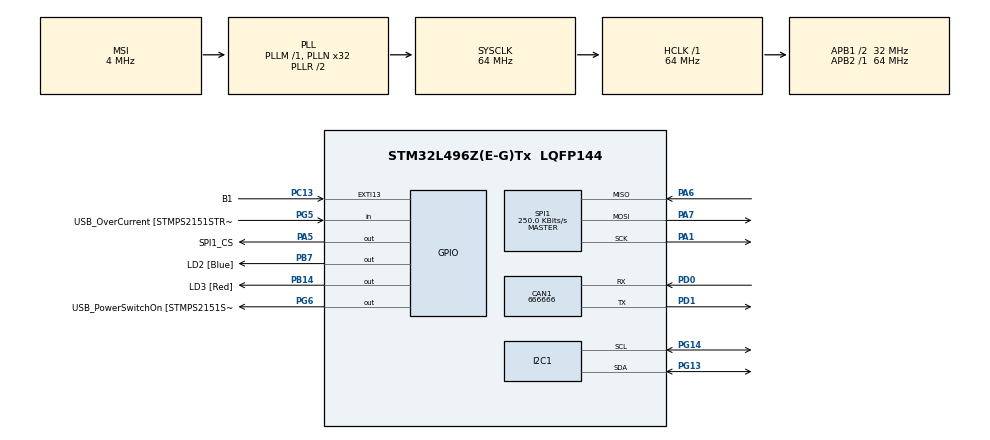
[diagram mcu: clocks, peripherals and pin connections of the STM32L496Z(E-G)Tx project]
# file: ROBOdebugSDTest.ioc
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CAN1.CalculateBaudRate=666666
CAN1.CalculateTimeBit=1500
CAN1.CalculateTimeQuantum=500.0
I2C1.Timing=0x00B07CB4
Mcu.Family=STM32L4
Mcu.Name=STM32L496Z(E-G)Tx
Mcu.Package=LQFP144
NVIC.PriorityGroup=NVIC_PRIORITYGROUP_4
PA1.GPIO_PuPd=GPIO_PULLUP
PA1.Mode=Full_Duplex_Master
PA1.Signal=SPI1_SCK
PA10.GPIO_Label=USB_ID
PA10.Signal=USB_OTG_FS_ID
PA11.GPIO_Label=USB_DM
PA11.Signal=USB_OTG_FS_DM
PA12.GPIO_Label=USB_DP
PA12.Signal=USB_OTG_FS_DP
PA13\ (JTMS/SWDIO).GPIO_Label=TMS
PA13\ (JTMS/SWDIO).Mode=Trace_Asynchronous_SW
PA13\ (JTMS/SWDIO).Signal=SYS_JTMS-SWDIO
PA14\ (JTCK/SWCLK).GPIO_Label=TCK
PA14\ (JTCK/SWCLK).Mode=Trace_Asynchronous_SW
PA14\ (JTCK/SWCLK).Signal=SYS_JTCK-SWCLK
PA5.GPIO_Label=SPI1_CS
PA5.GPIO_PuPd=GPIO_PULLUP
PA5.PinState=GPIO_PIN_SET
PA5.Signal=GPIO_Output
PA6.GPIO_PuPd=GPIO_PULLUP
PA6.Mode=Full_Duplex_Master
PA6.Signal=SPI1_MISO
PA7.GPIO_PuPd=GPIO_PULLUP
PA7.Mode=Full_Duplex_Master
PA7.Signal=SPI1_MOSI
PA8.GPIO_Label=USB_SOF [TP1]
PA8.Signal=USB_OTG_FS_SOF
PA9.GPIO_Label=USB_VBUS
PA9.Signal=USB_OTG_FS_VBUS
PB14.GPIO_Label=LD3 [Red]
PB14.Signal=GPIO_Output
PB3\ (JTDO/TRACESWO).GPIO_Label=SWO
PB3\ (JTDO/TRACESWO).Mode=Trace_Asynchronous_SW
PB3\ (JTDO/TRACESWO).Signal=SYS_JTDO-SWO
PB7.GPIO_Label=LD2 [Blue]
PB7.Signal=GPIO_Output
PC13.GPIO_Label=B1
PC13.Signal=GPXTI13
PC14-OSC32_IN\ (PC14).Mode=LSE-External-Oscillator
PC14-OSC32_IN\ (PC14).Signal=RCC_OSC32_IN
PC15-OSC32_OUT\ (PC15).Mode=LSE-External-Oscillator
PC15-OSC32_OUT\ (PC15).Signal=RCC_OSC32_OUT
PD0.Mode=CAN_Activate
PD0.Signal=CAN1_RX
PD1.Mode=CAN_Activate
PD1.Signal=CAN1_TX
PG13.Mode=I2C
PG13.Signal=I2C1_SDA
PG14.Mode=I2C
PG14.Signal=I2C1_SCL
PG5.GPIO_Label=USB_OverCurrent [STMPS2151STR_FAULT]
PG5.Signal=GPIO_Input
PG6.GPIO_Label=USB_PowerSwitchOn [STMPS2151STR_EN]
PG6.Signal=GPIO_Output
PG7.GPIO_Label=STLK_RX [STM32F103CBT6_PA3]
PG7.Signal=LPUART1_TX
PG8.GPIO_Label=STLK_TX [STM32F103CBT6_PA2]
PG8.Signal=LPUART1_RX
PH0-OSC_IN\ (PH0).Mode=HSE-External-Oscillator
PH0-OSC_IN\ (PH0).Signal=RCC_OSC_IN
PH1-OSC_OUT\ (PH1).Mode=HSE-External-Oscillator
PH1-OSC_OUT\ (PH1).Signal=RCC_OSC_OUT
ProjectManager.HeapSize=0x200
ProjectManager.StackSize=0x400
ProjectManager.TargetToolchain=STM32CubeIDE
RCC.48MHZClocksFreq_Value=24000000
RCC.ADCFreq_Value=48000000
RCC.AHBFreq_Value=64000000
RCC.APB1CLKDivider=RCC_HCLK_DIV2
RCC.APB1Freq_Value=32000000
RCC.APB1TimFreq_Value=64000000
RCC.APB2Freq_Value=64000000
RCC.APB2TimFreq_Value=64000000
RCC.CortexFreq_Value=64000000
RCC.HCLKFreq_Value=64000000
RCC.HSE_VALUE=8000000
RCC.HSI48_VALUE=48000000
RCC.HSI_VALUE=16000000
RCC.MSI_VALUE=4000000
RCC.PLLMUL=RCC_PLL_MUL9
RCC.PLLN=32
RCC.PLLSAI1N=24
RCC.PRESCALERUSB=RCC_USBCLKSOURCE_PLL_DIV1_5
RCC.SYSCLKFreq_VALUE=64000000
RCC.SYSCLKSource=RCC_SYSCLKSOURCE_PLLCLK
RCC.SYSCLKSourceVirtual=RCC_SYSCLKSOURCE_PLLCLK
RCC.USBFreq_Value=48000000
RCC.VCOOutputFreq_Value=128000000
SPI1.BaudRatePrescaler=SPI_BAUDRATEPRESCALER_256
SPI1.CalculateBaudRate=250.0 KBits/s
SPI1.DataSize=SPI_DATASIZE_8BIT
SPI1.Direction=SPI_DIRECTION_2LINES
SPI1.Mode=SPI_MODE_MASTER
SPI1.VirtualType=VM_MASTER
VP_FATFS_VS_Generic.Mode=User_defined
board=NUCLEO-L496ZG

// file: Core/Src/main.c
/* USER CODE BEGIN Header */
/**
  ******************************************************************************
  * @file           : main.c
  * @brief          : Main program body
  ******************************************************************************
  * @attention
  *
  * Copyright (c) 2025 STMicroelectronics.
  * All rights reserved.
  *
  * This software is licensed under terms that can be found in the LICENSE file
  * in the root directory of this software component.
  * If no LICENSE file comes with this software, it is provided AS-IS.
  *
  ******************************************************************************
  */
/* USER CODE END Header */
#include "main.h"
#include "fatfs.h"

/* USER CODE BEGIN Includes */
#include <stdlib.h>
#include <stdio.h>
#include <string.h>

/* USER CODE END Includes */

CAN_HandleTypeDef hcan1;

I2C_HandleTypeDef hi2c1;

SPI_HandleTypeDef hspi1;

void SystemClock_Config(void);
static void MX_GPIO_Init(void);
static void MX_CAN1_Init(void);
static void MX_I2C1_Init(void);
static void MX_SPI1_Init(void);

int main(void)
{

  /* MCU Configuration--------------------------------------------------------*/

  /* Reset of all peripherals, Initializes the Flash interface and the Systick. */
  HAL_Init();

  /* Configure the system clock */
  SystemClock_Config();

  /* Initialize all configured peripherals */
  MX_GPIO_Init();
  MX_CAN1_Init();
  MX_I2C1_Init();
  MX_SPI1_Init();
  MX_FATFS_Init();
//  /* USER CODE BEGIN 2 */
printf("SPI SD card test Initialing");
fflush(stdout);
HAL_Delay(1000);
FATFS FatFs;	//FatFs handle
FIL fil; 		//File handle
FRESULT fres; //Result after operations

//Open the file system
fres = f_mount(&FatFs, "", 1); //1=mount now
if (fres != FR_OK) {
	printf("f_mount error (%i)\r\n", fres);
	fflush(stdout);
	while(1);
}
DWORD free_clusters, free_sectors, total_sectors;

FATFS* getFreeFs;

fres = f_getfree("", &free_clusters, &getFreeFs);
if (fres != FR_OK) {
	printf("f_getfree error (%i)\r\n", fres);
	fflush(stdout);
	while(1);
}

//Formula comes from ChaN's documentation
total_sectors = (getFreeFs->n_fatent - 2) * getFreeFs->csize;
free_sectors = free_clusters * getFreeFs->csize;

printf("SD card stats:\r\n%10lu KiB total drive space.\r\n%10lu KiB available.\r\n", total_sectors / 2, free_sectors / 2);
fflush(stdout);
//----------------------------------------------------------------------------------
////Now let's try to open file "test.txt"
//fres = f_open(&fil, "test.txt", FA_READ);
//if (fres != FR_OK) {
//	myprintf("f_open error (%i)\r\n");
//	while(1);
//}
//myprintf("Opened 'test.txt' for reading!\r\n");
//
////Read 30 bytes from "test.txt" on the SD card
BYTE readBuf[30];
//
////We can either use f_read OR f_gets to get data out of files
////f_gets is a wrapper on f_read that does some string formatting for us
//TCHAR* rres = f_gets((TCHAR*)readBuf, 30, &fil);
//if(rres != 0) {
//	myprintf("Read string from 'test.txt' contents: %s\r\n", readBuf);
//} else {
//	myprintf("f_gets error (%i)\r\n", fres);
//}
//
//
//f_close(&fil);
//----------------------------------------------------------------------------------
//Now let's try and write a file "write.txt"
fres = f_open(&fil, "write.txt", FA_WRITE | FA_OPEN_ALWAYS | FA_CREATE_ALWAYS);
if(fres == FR_OK) {
	printf("Opened 'write.txt' for writing\r\n");
	fflush(stdout);
} else {
	printf("f_open error (%i)\r\n", fres);
	fflush(stdout);
}

//Copy in a string
strncpy((char*)readBuf, "a new file created", 19);
UINT bytesWrote;
fres = f_write(&fil, readBuf, 19, &bytesWrote);
if(fres == FR_OK) {
	printf("Wrote %i bytes to 'write.txt'!\r\n", bytesWrote);
	fflush(stdout);
} else {
	printf("f_write error (%i)\r\n");
	fflush(stdout);
}

f_close(&fil);

//We're done, so de-mount the drive
f_mount(NULL, "", 0);
  /* USER CODE END 2 */

  /* Infinite loop */
  while (1)
  {

    /* USER CODE BEGIN 3 */
	  printf("You can close the project now");
	  fflush(stdout); //flushes out everything from stdout buffer
	  HAL_Delay(5000);
  }
  // Data size - bits send per pulse
  // Pre scaler - SPI clk = sysclk/pre scaler
  /* USER CODE END 3 */
}

void SystemClock_Config(void)
{
  RCC_OscInitTypeDef RCC_OscInitStruct = {0};
  RCC_ClkInitTypeDef RCC_ClkInitStruct = {0};

  /** Configure the main internal regulator output voltage
  */
  if (HAL_PWREx_ControlVoltageScaling(PWR_REGULATOR_VOLTAGE_SCALE1) != HAL_OK)
  {
    Error_Handler();
  }

  /** Initializes the RCC Oscillators according to the specified parameters
  * in the RCC_OscInitTypeDef structure.
  */
  RCC_OscInitStruct.OscillatorType = RCC_OSCILLATORTYPE_MSI;
  RCC_OscInitStruct.MSIState = RCC_MSI_ON;
  RCC_OscInitStruct.MSICalibrationValue = 0;
  RCC_OscInitStruct.MSIClockRange = RCC_MSIRANGE_6;
  RCC_OscInitStruct.PLL.PLLState = RCC_PLL_ON;
  RCC_OscInitStruct.PLL.PLLSource = RCC_PLLSOURCE_MSI;
  RCC_OscInitStruct.PLL.PLLM = 1;
  RCC_OscInitStruct.PLL.PLLN = 32;
  RCC_OscInitStruct.PLL.PLLP = RCC_PLLP_DIV2;
  RCC_OscInitStruct.PLL.PLLQ = RCC_PLLQ_DIV2;
  RCC_OscInitStruct.PLL.PLLR = RCC_PLLR_DIV2;
  if (HAL_RCC_OscConfig(&RCC_OscInitStruct) != HAL_OK)
  {
    Error_Handler();
  }

  /** Initializes the CPU, AHB and APB buses clocks
  */
  RCC_ClkInitStruct.ClockType = RCC_CLOCKTYPE_HCLK|RCC_CLOCKTYPE_SYSCLK
                              |RCC_CLOCKTYPE_PCLK1|RCC_CLOCKTYPE_PCLK2;
  RCC_ClkInitStruct.SYSCLKSource = RCC_SYSCLKSOURCE_PLLCLK;
  RCC_ClkInitStruct.AHBCLKDivider = RCC_SYSCLK_DIV1;
  RCC_ClkInitStruct.APB1CLKDivider = RCC_HCLK_DIV2;
  RCC_ClkInitStruct.APB2CLKDivider = RCC_HCLK_DIV1;

  if (HAL_RCC_ClockConfig(&RCC_ClkInitStruct, FLASH_LATENCY_3) != HAL_OK)
  {
    Error_Handler();
  }
}

static void MX_CAN1_Init(void)
{

  hcan1.Instance = CAN1;
  hcan1.Init.Prescaler = 16;
  hcan1.Init.Mode = CAN_MODE_NORMAL;
  hcan1.Init.SyncJumpWidth = CAN_SJW_1TQ;
  hcan1.Init.TimeSeg1 = CAN_BS1_1TQ;
  hcan1.Init.TimeSeg2 = CAN_BS2_1TQ;
  hcan1.Init.TimeTriggeredMode = DISABLE;
  hcan1.Init.AutoBusOff = DISABLE;
  hcan1.Init.AutoWakeUp = DISABLE;
  hcan1.Init.AutoRetransmission = DISABLE;
  hcan1.Init.ReceiveFifoLocked = DISABLE;
  hcan1.Init.TransmitFifoPriority = DISABLE;
  if (HAL_CAN_Init(&hcan1) != HAL_OK)
  {
    Error_Handler();
  }

}

static void MX_I2C1_Init(void)
{

  hi2c1.Instance = I2C1;
  hi2c1.Init.Timing = 0x00B07CB4;
  hi2c1.Init.OwnAddress1 = 0;
  hi2c1.Init.AddressingMode = I2C_ADDRESSINGMODE_7BIT;
  hi2c1.Init.DualAddressMode = I2C_DUALADDRESS_DISABLE;
  hi2c1.Init.OwnAddress2 = 0;
  hi2c1.Init.OwnAddress2Masks = I2C_OA2_NOMASK;
  hi2c1.Init.GeneralCallMode = I2C_GENERALCALL_DISABLE;
  hi2c1.Init.NoStretchMode = I2C_NOSTRETCH_DISABLE;
  if (HAL_I2C_Init(&hi2c1) != HAL_OK)
  {
    Error_Handler();
  }

  /** Configure Analogue filter
  */
  if (HAL_I2CEx_ConfigAnalogFilter(&hi2c1, I2C_ANALOGFILTER_ENABLE) != HAL_OK)
  {
    Error_Handler();
  }

  /** Configure Digital filter
  */
  if (HAL_I2CEx_ConfigDigitalFilter(&hi2c1, 0) != HAL_OK)
  {
    Error_Handler();
  }

}

static void MX_SPI1_Init(void)
{

  /* SPI1 parameter configuration*/
  hspi1.Instance = SPI1;
  hspi1.Init.Mode = SPI_MODE_MASTER;
  hspi1.Init.Direction = SPI_DIRECTION_2LINES;
  hspi1.Init.DataSize = SPI_DATASIZE_8BIT;
  hspi1.Init.CLKPolarity = SPI_POLARITY_LOW;
  hspi1.Init.CLKPhase = SPI_PHASE_1EDGE;
  hspi1.Init.NSS = SPI_NSS_SOFT;
  hspi1.Init.BaudRatePrescaler = SPI_BAUDRATEPRESCALER_256;
  hspi1.Init.FirstBit = SPI_FIRSTBIT_MSB;
  hspi1.Init.TIMode = SPI_TIMODE_DISABLE;
  hspi1.Init.CRCCalculation = SPI_CRCCALCULATION_DISABLE;
  hspi1.Init.CRCPolynomial = 7;
  hspi1.Init.CRCLength = SPI_CRC_LENGTH_DATASIZE;
  hspi1.Init.NSSPMode = SPI_NSS_PULSE_ENABLE;
  if (HAL_SPI_Init(&hspi1) != HAL_OK)
  {
    Error_Handler();
  }

}

static void MX_GPIO_Init(void)
{
  GPIO_InitTypeDef GPIO_InitStruct = {0};

  /* GPIO Ports Clock Enable */
  __HAL_RCC_GPIOC_CLK_ENABLE();
  __HAL_RCC_GPIOH_CLK_ENABLE();
  __HAL_RCC_GPIOA_CLK_ENABLE();
  __HAL_RCC_GPIOB_CLK_ENABLE();
  __HAL_RCC_GPIOG_CLK_ENABLE();
  HAL_PWREx_EnableVddIO2();
  __HAL_RCC_GPIOD_CLK_ENABLE();

  /*Configure GPIO pin Output Level */
  HAL_GPIO_WritePin(SPI1_CS_GPIO_Port, SPI1_CS_Pin, GPIO_PIN_SET);

  /*Configure GPIO pin Output Level */
  HAL_GPIO_WritePin(GPIOB, LD3_Pin|LD2_Pin, GPIO_PIN_RESET);

  /*Configure GPIO pin Output Level */
  HAL_GPIO_WritePin(USB_PowerSwitchOn_GPIO_Port, USB_PowerSwitchOn_Pin, GPIO_PIN_RESET);

  /*Configure GPIO pin : B1_Pin */
  GPIO_InitStruct.Pin = B1_Pin;
  GPIO_InitStruct.Mode = GPIO_MODE_IT_RISING;
  GPIO_InitStruct.Pull = GPIO_NOPULL;
  HAL_GPIO_Init(B1_GPIO_Port, &GPIO_InitStruct);

  /*Configure GPIO pin : SPI1_CS_Pin */
  GPIO_InitStruct.Pin = SPI1_CS_Pin;
  GPIO_InitStruct.Mode = GPIO_MODE_OUTPUT_PP;
  GPIO_InitStruct.Pull = GPIO_PULLUP;
  GPIO_InitStruct.Speed = GPIO_SPEED_FREQ_LOW;
  HAL_GPIO_Init(SPI1_CS_GPIO_Port, &GPIO_InitStruct);

  /*Configure GPIO pins : LD3_Pin LD2_Pin */
  GPIO_InitStruct.Pin = LD3_Pin|LD2_Pin;
  GPIO_InitStruct.Mode = GPIO_MODE_OUTPUT_PP;
  GPIO_InitStruct.Pull = GPIO_NOPULL;
  GPIO_InitStruct.Speed = GPIO_SPEED_FREQ_LOW;
  HAL_GPIO_Init(GPIOB, &GPIO_InitStruct);

  /*Configure GPIO pin : USB_OverCurrent_Pin */
  GPIO_InitStruct.Pin = USB_OverCurrent_Pin;
  GPIO_InitStruct.Mode = GPIO_MODE_INPUT;
  GPIO_InitStruct.Pull = GPIO_NOPULL;
  HAL_GPIO_Init(USB_OverCurrent_GPIO_Port, &GPIO_InitStruct);

  /*Configure GPIO pin : USB_PowerSwitchOn_Pin */
  GPIO_InitStruct.Pin = USB_PowerSwitchOn_Pin;
  GPIO_InitStruct.Mode = GPIO_MODE_OUTPUT_PP;
  GPIO_InitStruct.Pull = GPIO_NOPULL;
  GPIO_InitStruct.Speed = GPIO_SPEED_FREQ_LOW;
  HAL_GPIO_Init(USB_PowerSwitchOn_GPIO_Port, &GPIO_InitStruct);

  /*Configure GPIO pins : STLK_RX_Pin STLK_TX_Pin */
  GPIO_InitStruct.Pin = STLK_RX_Pin|STLK_TX_Pin;
  GPIO_InitStruct.Mode = GPIO_MODE_AF_PP;
  GPIO_InitStruct.Pull = GPIO_NOPULL;
  GPIO_InitStruct.Speed = GPIO_SPEED_FREQ_VERY_HIGH;
  GPIO_InitStruct.Alternate = GPIO_AF8_LPUART1;
  HAL_GPIO_Init(GPIOG, &GPIO_InitStruct);

  /*Configure GPIO pins : USB_SOF_Pin USB_ID_Pin USB_DM_Pin USB_DP_Pin */
  GPIO_InitStruct.Pin = USB_SOF_Pin|USB_ID_Pin|USB_DM_Pin|USB_DP_Pin;
  GPIO_InitStruct.Mode = GPIO_MODE_AF_PP;
  GPIO_InitStruct.Pull = GPIO_NOPULL;
  GPIO_InitStruct.Speed = GPIO_SPEED_FREQ_VERY_HIGH;
  GPIO_InitStruct.Alternate = GPIO_AF10_OTG_FS;
  HAL_GPIO_Init(GPIOA, &GPIO_InitStruct);

}

void Error_Handler(void)
{
  __disable_irq();
  while (1)
  {
  }
}
